# STM32WBA52 register map
File version: 1.3
CPU: CM33 r0p1, little endian, MPU, FPU, 4 interrupt priority bits
Registers are 32-bit, read-write, reset 0x0 unless marked. A register's access mark holds for its fields unless they carry their own. Offsets are from the block's base; [hi:lo] are bit positions.

## CRC — CRC register block
Base 0x40023000
Same registers: SEC_CRC 0x50023000
0x00 DR reset 0xFFFFFFFF — CRC data register
  [31:0] DR — Data register bits This register is used to write new data to the CRC calculator. It holds the previous CRC calculation result when it is read. If the data size is less than 32 bits, the least significant bits are used to write/read the correct value.
0x00 DR8 8-bit reset 0xFF (alternate view of DR) — Data register - byte sized
  [7:0] DR8 — Data register bits
0x00 DR16 16-bit reset 0xFFFF (alternate view of DR) — Data register - half-word sized
  [15:0] DR16 — Data register bits
0x04 IDR — CRC independent data register
  [31:0] IDR — General-purpose 32-bit data register bits These bits can be used as a temporary storage location for four bytes. This register is not affected by CRC resets generated by the RESET bit in the CRC_CR register
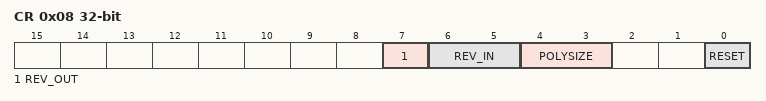
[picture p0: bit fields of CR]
0x08 CR — CRC control register
  [7] REV_OUT — Reverse output data This bit controls the reversal of the bit order of the output data.
    0=Normal (Bit order not affected); 1=Reversed (Bit reversed output)
  [6:5] REV_IN — Reverse input data These bits control the reversal of the bit order of the input data
    0=Normal (Bit order not affected); 1=Byte (Bit reversal done by byte); 2=HalfWord (Bit reversal done by half-word); 3=Word (Bit reversal done by word)
  [4:3] POLYSIZE — Polynomial size These bits control the size of the polynomial.
    0=32-bit polynomial; 1=16-bit polynomial; 2=8-bit polynomial; 3=7-bit polynomial
  [0] RESET — RESET bit This bit is set by software to reset the CRC calculation unit and set the data register to the value stored in the CRC_INIT register. This bit can only be set, it is automatically cleared by hardware
    on write: 1=Resets the CRC calculation unit and sets the data register to 0xFFFF FFFF
0x10 INIT reset 0xFFFFFFFF — CRC initial value
  [31:0] INIT — Programmable initial CRC value This register is used to write the CRC initial value.
0x14 POL reset 0x4C11DB7 — CRC polynomial
  [31:0] POL — Programmable polynomial This register is used to write the coefficients of the polynomial to be used for CRC calculation. If the polynomial size is less than 32 bits, the least significant bits have to be used to program the correct value.

## GTZC1_TZSC
Base 0x40032400
Same registers: SEC_GTZC1_TZSC 0x50032400
0x00 CR — GTZC1 TZSC control register
  [0] LCK — lock the configuration of GTZC1_TZSC_SECCFGRn and GTZC1_TZSC_PRIVCFGRn registers until next reset This bit is cleared by default and once set, it can not be reset until system reset.
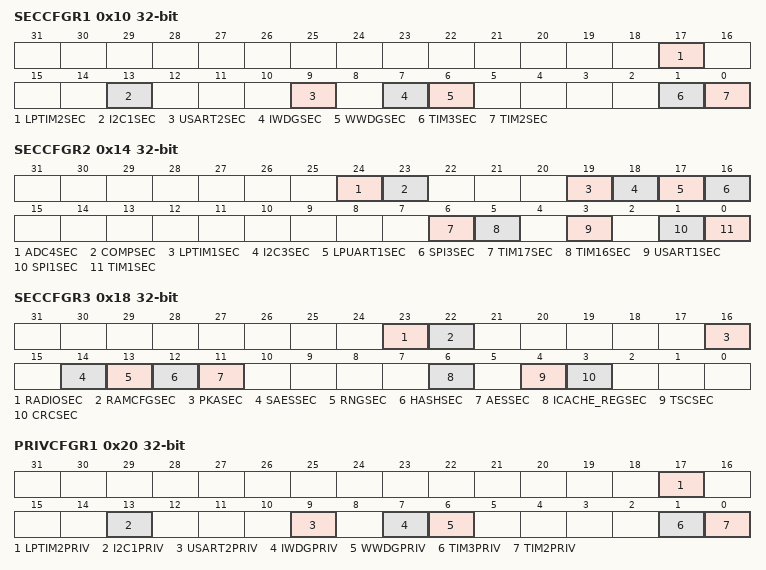
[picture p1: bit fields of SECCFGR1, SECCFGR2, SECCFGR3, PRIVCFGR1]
0x10 SECCFGR1 — GTZC1 TZSC secure configuration register 1
  [17] LPTIM2SEC — secure access mode for LPTIM2
  [13] I2C1SEC — secure access mode for I2C1
  [9] USART2SEC — secure access mode for USART2
  [7] IWDGSEC — secure access mode for IWDG
  [6] WWDGSEC — secure access mode for WWDG
  [1] TIM3SEC — secure access mode for TIM3
  [0] TIM2SEC — secure access mode for TIM2
0x14 SECCFGR2 — GTZC1 TZSC secure configuration register 2
  [24] ADC4SEC — secure access mode for ADC4
  [23] COMPSEC — secure access mode for COMP Note that bit 23 is reserved on sales type STM32WBA52.
  [19] LPTIM1SEC — secure access mode for LPTIM1
  [18] I2C3SEC — secure access mode for I2C3
  [17] LPUART1SEC — secure access mode for LPUART1
  [16] SPI3SEC — secure access mode for SPI3
  [6] TIM17SEC — secure access mode for TIM17
  [5] TIM16SEC — secure access mode for TIM16
  [3] USART1SEC — secure access mode for USART1
  [1] SPI1SEC — secure access mode for SPI1
  [0] TIM1SEC — secure access mode for TIM1
0x18 SECCFGR3 — GTZC1 TZSC secure configuration register 3
  [23] RADIOSEC — secure access mode for 2.4 GHz RADIO
  [22] RAMCFGSEC — secure access mode for RAMCFG
  [16] PKASEC — secure access mode for PKA
  [14] SAESSEC — secure access mode for SAES
  [13] RNGSEC — secure access mode for RNG
  [12] HASHSEC — secure access mode for HASH
  [11] AESSEC — secure access mode for AES
  [6] ICACHE_REGSEC — secure access mode for ICACHE registers
  [4] TSCSEC — secure access mode for TSC
  [3] CRCSEC — secure access mode for CRC
0x20 PRIVCFGR1 — GTZC1 TZSC privilege configuration register 1
  [17] LPTIM2PRIV — privileged access mode for LPTIM2
  [13] I2C1PRIV — privileged access mode for I2C1
  [9] USART2PRIV — privileged access mode for USART2
  [7] IWDGPRIV — privileged access mode for IWDG
  [6] WWDGPRIV — privileged access mode for WWDG
  [1] TIM3PRIV — privileged access mode for TIM3
  [0] TIM2PRIV — privileged access mode for TIM2
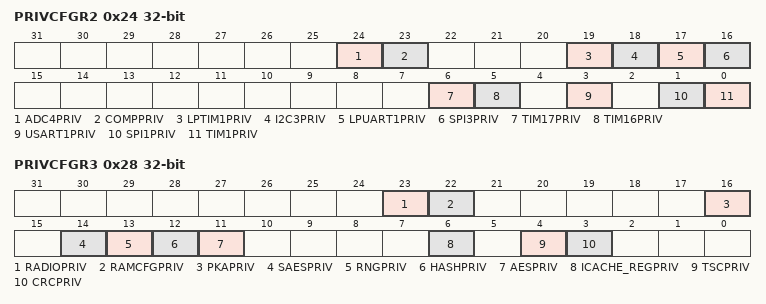
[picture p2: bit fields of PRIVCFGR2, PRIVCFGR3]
0x24 PRIVCFGR2 — GTZC1 TZSC privilege configuration register 2
  [24] ADC4PRIV — privileged access mode for ADC4
  [23] COMPPRIV — privileged access mode for COMP Note that bit 23 is reserved on sales type STM32WBA52.
  [19] LPTIM1PRIV — privileged access mode for LPTIM1
  [18] I2C3PRIV — privileged access mode for I2C3
  [17] LPUART1PRIV — privileged access mode for LPUART1
  [16] SPI3PRIV — privileged access mode for SPI3
  [6] TIM17PRIV — privileged access mode for TIM17
  [5] TIM16PRIV — privileged access mode for TIM16
  [3] USART1PRIV — privileged access mode for USART1
  [1] SPI1PRIV — privileged access mode for SPI1PRIV
  [0] TIM1PRIV — privileged access mode for TIM1
0x28 PRIVCFGR3 — GTZC1 TZSC privilege configuration register 3
  [23] RADIOPRIV — privileged access mode for 2.4 GHz RADIO
  [22] RAMCFGPRIV — privileged access mode for RAMCFG
  [16] PKAPRIV — privileged access mode for PKA
  [14] SAESPRIV — privileged access mode for SAES
  [13] RNGPRIV — privileged access mode for RNG
  [12] HASHPRIV — privileged access mode for HASH
  [11] AESPRIV — privileged access mode for AES
  [6] ICACHE_REGPRIV — privileged access mode for ICACHE registers
  [4] TSCPRIV — privileged access mode for TSC
  [3] CRCPRIV — privileged access mode for CRC
